CM_ "IMPORT _hyundai_can_common.dbc";

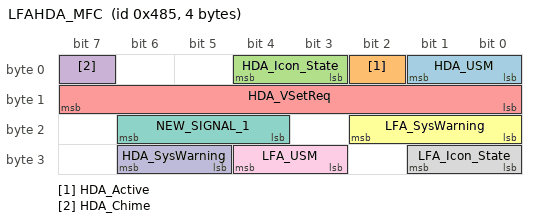
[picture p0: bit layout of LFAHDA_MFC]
BO_ 1157 LFAHDA_MFC: 4 XXX
 SG_ HDA_USM : 0|2@1+ (1,0) [0|3] "" XXX
 SG_ HDA_Active : 2|1@1+ (1,0) [0|1] "" XXX
 SG_ HDA_Icon_State : 3|2@1+ (1,0) [0|3] "" XXX
 SG_ HDA_Chime : 7|1@1+ (1,0) [0|1] "" XXX
 SG_ HDA_VSetReq : 8|8@1+ (1,0) [0|255] "km/h" XXX
 SG_ LFA_SysWarning : 16|3@1+ (1,0) [0|7] "" XXX
 SG_ NEW_SIGNAL_1 : 20|3@1+ (1,0) [0|7] "" XXX
 SG_ LFA_Icon_State : 24|2@1+ (1,0) [0|3] "" XXX
 SG_ LFA_USM : 27|2@1+ (1,0) [0|3] "" XXX
 SG_ HDA_SysWarning : 29|2@1+ (1,0) [0|3] "" XXX

VAL_ 1157 HDA_Icon_State 0 "no_hda" 1 "white_hda" 2 "green_hda";
VAL_ 1157 LFA_SysWarning 0 "no_message" 1 "switching_to_hda" 2 "switching_to_scc" 3 "lfa_error" 4 "check_hda" 5 "keep_hands_on_wheel_orange" 6 "keep_hands_on_wheel_red";
VAL_ 1157 LFA_Icon_State 0 "no_wheel" 1 "white_wheel" 2 "green_wheel" 3 "green_wheel_blink";
VAL_ 1157 HDA_SysWarning 0 "no_message" 1 "driving_convenience_systems_cancelled" 2 "highway_drive_assist_system_cancelled";
